VERSION ""

NS_ :

BS_:

BU_:

BO_ 1543 EtasVCSeat_row1ZPosition: 2 Vector__XXX
 SG_ EtasVCSeat_row1ZPosition : 0|16@1+ (1,0) [0|0] "mm" Vector__XXX

BO_ 1542 EtasVCSeat_row1XPosition: 2 Vector__XXX
 SG_ EtasVCSeat_row1XPosition : 0|16@1+ (1,0) [0|0] "mm" Vector__XXX

BO_ 1541 EtasVCRIGHT_mirrorTiltYPosition: 1 Vector__XXX
 SG_ EtasVCRIGHT_mirrorTiltYPosition : 0|8@1+ (1,0) [0|0] "percent" Vector__XXX

BO_ 1540 EtasVCRIGHT_mirrorTiltXPosition: 1 Vector__XXX
 SG_ EtasVCRIGHT_mirrorTiltXPosition : 0|8@1+ (1,0) [0|0] "percent" Vector__XXX

BO_ 1538 EtasVCLEFT_mirrorTiltXPosition: 1 Vector__XXX
 SG_ EtasVCLEFT_mirrorTiltXPosition : 0|8@1+ (1,0) [0|0] "percent" Vector__XXX

BO_ 1539 EtasVCLEFT_mirrorTiltYPosition: 1 Vector__XXX
 SG_ EtasVCLEFT_mirrorTiltYPosition : 0|8@1+ (1,0) [0|0] "percent" Vector__XXX

BO_ 1537 EtasVCFRONT_tempAmbientFiltered: 4 Vector__XXX
 SG_ EtasVCFRONT_tempAmbientFiltered : 0|32@1- (1,0) [0|0] "celsius" Vector__XXX

BO_ 1536 EtasSteeringAngle129: 2 Vector__XXX
 SG_ EtasSteeringAngle129 : 0|16@1- (1,0) [0|0] "degrees" Vector__XXX

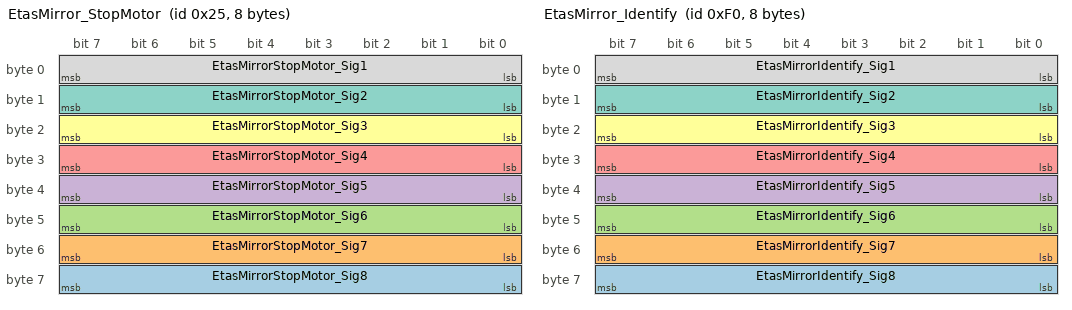
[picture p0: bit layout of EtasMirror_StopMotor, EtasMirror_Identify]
BO_ 37 EtasMirror_StopMotor: 8 Vector__XXX
 SG_ EtasMirrorStopMotor_Sig8 : 56|8@1+ (1,0) [0|0] "" Vector__XXX
 SG_ EtasMirrorStopMotor_Sig7 : 48|8@1+ (1,0) [0|0] "" Vector__XXX
 SG_ EtasMirrorStopMotor_Sig6 : 40|8@1+ (1,0) [0|0] "" Vector__XXX
 SG_ EtasMirrorStopMotor_Sig5 : 32|8@1+ (1,0) [0|0] "" Vector__XXX
 SG_ EtasMirrorStopMotor_Sig4 : 24|8@1+ (1,0) [0|0] "" Vector__XXX
 SG_ EtasMirrorStopMotor_Sig3 : 16|8@1+ (1,0) [0|0] "" Vector__XXX
 SG_ EtasMirrorStopMotor_Sig2 : 8|8@1+ (1,0) [0|0] "" Vector__XXX
 SG_ EtasMirrorStopMotor_Sig1 : 0|8@1+ (1,0) [0|0] "" Vector__XXX

BO_ 240 EtasMirror_Identify: 8 Vector__XXX
 SG_ EtasMirrorIdentify_Sig8 : 56|8@1+ (1,0) [0|0] "" Vector__XXX
 SG_ EtasMirrorIdentify_Sig7 : 48|8@1+ (1,0) [0|0] "" Vector__XXX
 SG_ EtasMirrorIdentify_Sig6 : 40|8@1+ (1,0) [0|0] "" Vector__XXX
 SG_ EtasMirrorIdentify_Sig5 : 32|8@1+ (1,0) [0|0] "" Vector__XXX
 SG_ EtasMirrorIdentify_Sig4 : 24|8@1+ (1,0) [0|0] "" Vector__XXX
 SG_ EtasMirrorIdentify_Sig3 : 16|8@1+ (1,0) [0|0] "" Vector__XXX
 SG_ EtasMirrorIdentify_Sig2 : 8|8@1+ (1,0) [0|0] "" Vector__XXX
 SG_ EtasMirrorIdentify_Sig1 : 0|8@1+ (1,0) [0|0] "" Vector__XXX

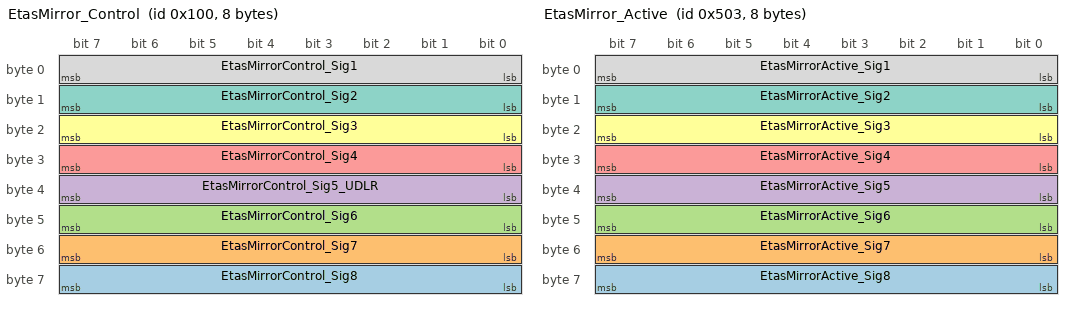
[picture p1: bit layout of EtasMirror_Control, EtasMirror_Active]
BO_ 256 EtasMirror_Control: 8 Vector__XXX
 SG_ EtasMirrorControl_Sig8 : 56|8@1+ (1,0) [0|0] "" Vector__XXX
 SG_ EtasMirrorControl_Sig7 : 48|8@1+ (1,0) [0|0] "" Vector__XXX
 SG_ EtasMirrorControl_Sig6 : 40|8@1+ (1,0) [0|0] "" Vector__XXX
 SG_ EtasMirrorControl_Sig5_UDLR : 32|8@1+ (1,0) [0|0] "" Vector__XXX
 SG_ EtasMirrorControl_Sig4 : 24|8@1+ (1,0) [0|0] "" Vector__XXX
 SG_ EtasMirrorControl_Sig3 : 16|8@1+ (1,0) [0|0] "" Vector__XXX
 SG_ EtasMirrorControl_Sig2 : 8|8@1+ (1,0) [0|0] "" Vector__XXX
 SG_ EtasMirrorControl_Sig1 : 0|8@1+ (1,0) [0|0] "" Vector__XXX

BO_ 1283 EtasMirror_Active: 8 Vector__XXX
 SG_ EtasMirrorActive_Sig8 : 56|8@1+ (1,0) [0|0] "" Vector__XXX
 SG_ EtasMirrorActive_Sig7 : 48|8@1+ (1,0) [0|0] "" Vector__XXX
 SG_ EtasMirrorActive_Sig6 : 40|8@1+ (1,0) [0|0] "" Vector__XXX
 SG_ EtasMirrorActive_Sig5 : 32|8@1+ (1,0) [0|0] "" Vector__XXX
 SG_ EtasMirrorActive_Sig4 : 24|8@1+ (1,0) [0|0] "" Vector__XXX
 SG_ EtasMirrorActive_Sig3 : 16|8@1+ (1,0) [0|0] "" Vector__XXX
 SG_ EtasMirrorActive_Sig2 : 8|8@1+ (1,0) [0|0] "" Vector__XXX
 SG_ EtasMirrorActive_Sig1 : 0|8@1+ (1,0) [0|0] "" Vector__XXX

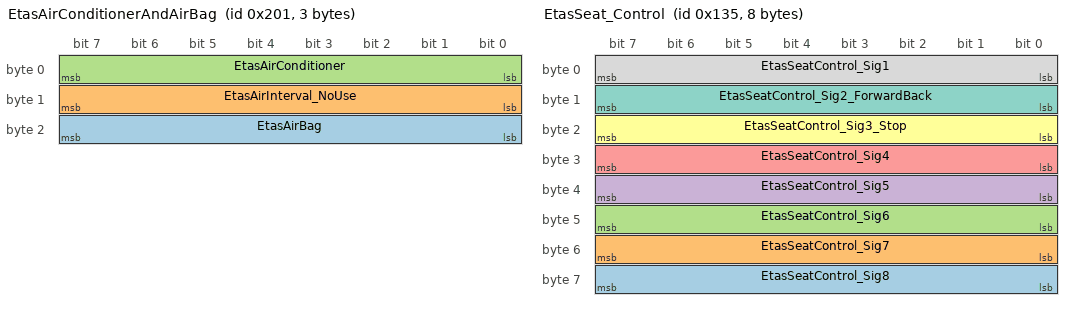
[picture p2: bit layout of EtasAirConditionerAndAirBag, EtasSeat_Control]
BO_ 513 EtasAirConditionerAndAirBag: 3 Vector__XXX
 SG_ EtasAirBag : 16|8@1+ (1,0) [0|0] "" Vector__XXX
 SG_ EtasAirInterval_NoUse : 8|8@1+ (1,0) [0|0] "" Vector__XXX
 SG_ EtasAirConditioner : 0|8@1+ (1,0) [0|0] "" Vector__XXX

BO_ 309 EtasSeat_Control: 8 Vector__XXX
 SG_ EtasSeatControl_Sig8 : 56|8@1+ (1,0) [0|0] "" Vector__XXX
 SG_ EtasSeatControl_Sig7 : 48|8@1+ (1,0) [0|0] "" Vector__XXX
 SG_ EtasSeatControl_Sig6 : 40|8@1+ (1,0) [0|0] "" Vector__XXX
 SG_ EtasSeatControl_Sig5 : 32|8@1+ (1,0) [0|0] "" Vector__XXX
 SG_ EtasSeatControl_Sig4 : 24|8@1+ (1,0) [0|0] "" Vector__XXX
 SG_ EtasSeatControl_Sig3_Stop : 16|8@1+ (1,0) [0|0] "" Vector__XXX
 SG_ EtasSeatControl_Sig2_ForwardBack : 8|8@1+ (1,0) [0|0] "" Vector__XXX
 SG_ EtasSeatControl_Sig1 : 0|8@1+ (1,0) [0|0] "" Vector__XXX

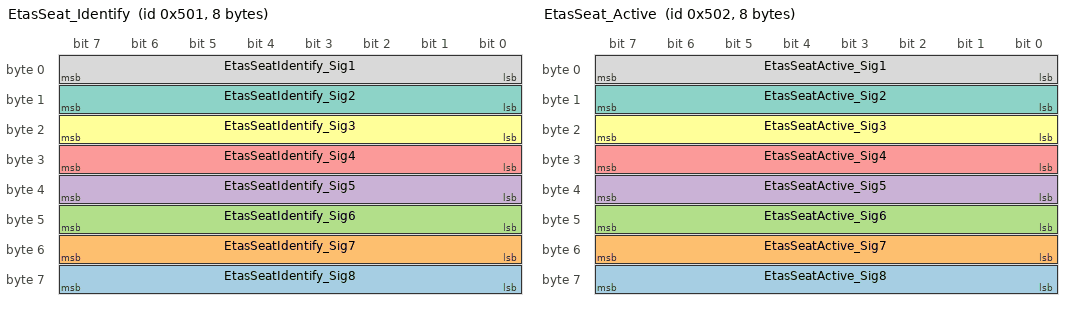
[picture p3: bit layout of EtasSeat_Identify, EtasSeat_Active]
BO_ 1281 EtasSeat_Identify: 8 Vector__XXX
 SG_ EtasSeatIdentify_Sig8 : 56|8@1+ (1,0) [0|0] "" Vector__XXX
 SG_ EtasSeatIdentify_Sig7 : 48|8@1+ (1,0) [0|0] "" Vector__XXX
 SG_ EtasSeatIdentify_Sig6 : 40|8@1+ (1,0) [0|0] "" Vector__XXX
 SG_ EtasSeatIdentify_Sig5 : 32|8@1+ (1,0) [0|0] "" Vector__XXX
 SG_ EtasSeatIdentify_Sig4 : 24|8@1+ (1,0) [0|0] "" Vector__XXX
 SG_ EtasSeatIdentify_Sig3 : 16|8@1+ (1,0) [0|0] "" Vector__XXX
 SG_ EtasSeatIdentify_Sig2 : 8|8@1+ (1,0) [0|0] "" Vector__XXX
 SG_ EtasSeatIdentify_Sig1 : 0|8@1+ (1,0) [0|0] "" Vector__XXX

BO_ 1282 EtasSeat_Active: 8 Vector__XXX
 SG_ EtasSeatActive_Sig8 : 56|8@1+ (1,0) [0|0] "" Vector__XXX
 SG_ EtasSeatActive_Sig7 : 48|8@1+ (1,0) [0|0] "" Vector__XXX
 SG_ EtasSeatActive_Sig6 : 40|8@1+ (1,0) [0|0] "" Vector__XXX
 SG_ EtasSeatActive_Sig5 : 32|8@1+ (1,0) [0|0] "" Vector__XXX
 SG_ EtasSeatActive_Sig4 : 24|8@1+ (1,0) [0|0] "" Vector__XXX
 SG_ EtasSeatActive_Sig3 : 16|8@1+ (1,0) [0|0] "" Vector__XXX
 SG_ EtasSeatActive_Sig2 : 8|8@1+ (1,0) [0|0] "" Vector__XXX
 SG_ EtasSeatActive_Sig1 : 0|8@1+ (1,0) [0|0] "" Vector__XXX

BO_ 599 EtasVehicleSpeed: 4 Vector__XXX
 SG_ EtasVehicleSpeed : 0|32@1- (0.08,-40) [-40|285] "km/h" Vector__XXX

EV_ EnvKlemme30: 0 [0|1] "" 1 1 DUMMY_NODE_VECTOR0 Vector__XXX;

EV_ EnvKlemme15: 0 [0|1] "" 0 2 DUMMY_NODE_VECTOR0 Vector__XXX;

BA_DEF_ BU_  "NodeLayerModules" STRING ;
BA_DEF_ BO_  "GenMsgILSupport" ENUM  "No","Yes";
BA_DEF_  "NmBaseAddress" HEX 1024 1087;
BA_DEF_ BO_  "GenMsgSendType" ENUM  "Cyclic","NotUsed","NotUsed","NotUsed","NotUsed","NotUsed","NotUsed","IfActive","NoMsgSendType","NotUsed","vector_leerstring";
BA_DEF_ SG_  "GenSigSendType" ENUM  "Cyclic","OnWrite","OnWriteWithRepetition","OnChange","OnChangeWithRepetition","IfActive","IfActiveWithRepetition","NoSigSendType","NotUsed","NotUsed","NotUsed","NotUsed","NotUsed";
BA_DEF_ SG_  "GenSigStartValue" FLOAT 0 100000000000;
BA_DEF_DEF_  "NodeLayerModules" "CANoeILNLVector.dll";
BA_DEF_DEF_  "GenMsgILSupport" "Yes";
BA_DEF_DEF_  "NmBaseAddress" 1024;
BA_DEF_DEF_  "GenMsgSendType" "NoMsgSendType";
BA_DEF_DEF_  "GenSigSendType" "Cyclic";
BA_DEF_DEF_  "GenSigStartValue" 0;
BA_ "GenSigStartValue" SG_ 599 EtasVehicleSpeed 500;
SIG_VALTYPE_ 1537 EtasVCFRONT_tempAmbientFiltered : 1;
SIG_VALTYPE_ 599 EtasVehicleSpeed : 1;
